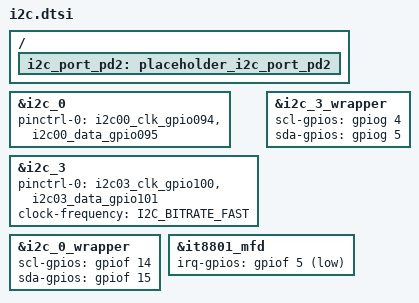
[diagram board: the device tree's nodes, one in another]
/* Copyright 2025 The ChromiumOS Authors
 * Use of this source code is governed by a BSD-style license that can be
 * found in the LICENSE file.
 */

i2c_port_charger: &i2c_0 {
	pinctrl-0 = <&i2c00_clk_gpio094
		     &i2c00_data_gpio095>;
	pinctrl-names = "default";
	status = "okay";

};

i2c_port_pd1: &i2c_3 {
	pinctrl-0 = <&i2c03_clk_gpio100
		     &i2c03_data_gpio101>;
	pinctrl-names = "default";
	status = "okay";

	clock-frequency = <I2C_BITRATE_FAST>;
};

/ {
	i2c_port_pd2: placeholder_i2c_port_pd2 {

	};
	i2c_port_ish: placeholder_i2c_port_ish {

	};
};


&i2c_0_wrapper {
	status = "okay";
	scl-gpios = <&gpiof 14 GPIO_ACTIVE_HIGH>;
	sda-gpios = <&gpiof 15 GPIO_ACTIVE_HIGH>;
};

&i2c_3_wrapper {
	status = "okay";
	scl-gpios = <&gpiog 4 GPIO_ACTIVE_HIGH>;
	sda-gpios = <&gpiog 5 GPIO_ACTIVE_HIGH>;
};

#include "../rvp_i2c.dtsi"
#include <ite/it8801-common-cfg.dtsi>


&it8801_mfd {
	irq-gpios = <&gpiof 5 GPIO_ACTIVE_LOW>;
};

/delete-node/ &i2c_named_i2c_port_pd2;
/delete-node/ &i2c_named_i2c_port_ish;
/delete-node/ &i2c_port_ish;
